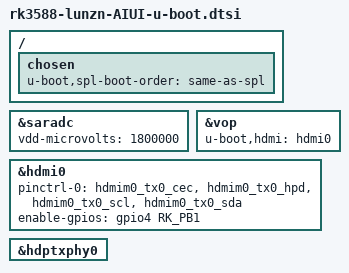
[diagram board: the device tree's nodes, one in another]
// SPDX-License-Identifier: (GPL-2.0+ OR MIT)
#include "rk3588-u-boot.dtsi"

/ {
	chosen {
		u-boot,spl-boot-order = "same-as-spl", &sdmmc, &sdhci;
	};
};

&saradc {
	vdd-microvolts = <1800000>;
};

&vop {
	u-boot,hdmi = <&hdmi0>;
	status = "okay";
};

&hdmi0 {
	pinctrl-names = "default";
	pinctrl-0 = <&hdmim0_tx0_cec &hdmim0_tx0_hpd
		     &hdmim0_tx0_scl &hdmim0_tx0_sda>;
	enable-gpios = <&gpio4 RK_PB1 GPIO_ACTIVE_HIGH>;
	status = "okay";
};

&hdptxphy0 {
	status = "okay";
};
